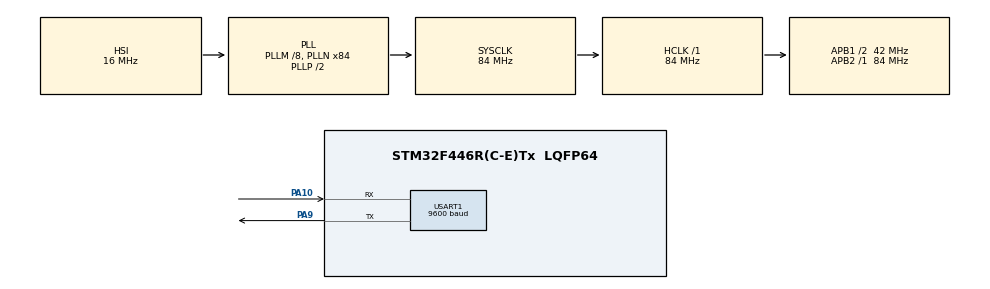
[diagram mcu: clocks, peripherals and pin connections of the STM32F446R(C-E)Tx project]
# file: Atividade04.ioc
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FREERTOS.Tasks01=Task01,24,128,StartTask01,Default,NULL,Dynamic,NULL,NULL;Task02,40,128,StartTask02,Default,NULL,Dynamic,NULL,NULL
FREERTOS.configUSE_NEWLIB_REENTRANT=1
Mcu.Family=STM32F4
Mcu.Name=STM32F446R(C-E)Tx
Mcu.Package=LQFP64
NVIC.PriorityGroup=NVIC_PRIORITYGROUP_4
NVIC.TIM1_UP_TIM10_IRQn=true\:15\:0\:false\:false\:true\:false\:false\:true\:true
NVIC.TimeBase=TIM1_UP_TIM10_IRQn
NVIC.TimeBaseIP=TIM1
PA10.Mode=Asynchronous
PA10.Signal=USART1_RX
PA13.Mode=Serial_Wire
PA13.Signal=SYS_JTMS-SWDIO
PA14.Mode=Serial_Wire
PA14.Signal=SYS_JTCK-SWCLK
PA9.Mode=Asynchronous
PA9.Signal=USART1_TX
ProjectManager.HeapSize=0x200
ProjectManager.StackSize=0x400
ProjectManager.TargetToolchain=STM32CubeIDE
RCC.AHBFreq_Value=84000000
RCC.APB1CLKDivider=RCC_HCLK_DIV2
RCC.APB1Freq_Value=42000000
RCC.APB1TimFreq_Value=84000000
RCC.APB2Freq_Value=84000000
RCC.APB2TimFreq_Value=84000000
RCC.CortexFreq_Value=84000000
RCC.FLatency-AdvancedSettings=FLASH_LATENCY_2
RCC.HCLKFreq_Value=84000000
RCC.HSE_VALUE=8000000
RCC.HSI_VALUE=16000000
RCC.LSE_VALUE=32768
RCC.PLLM=8
RCC.PLLN=84
RCC.SYSCLKFreq_VALUE=84000000
RCC.SYSCLKSource=RCC_SYSCLKSOURCE_PLLCLK
RCC.USBFreq_Value=84000000
RCC.VCOOutputFreq_Value=168000000
USART1.BaudRate=9600
USART1.VirtualMode=VM_ASYNC
VP_FREERTOS_VS_CMSIS_V2.Mode=CMSIS_V2
VP_SYS_VS_tim1.Mode=TIM1
board=NUCLEO-F446RE

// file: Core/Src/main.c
/* USER CODE BEGIN Header */
/**
  ******************************************************************************
  * @file           : main.c
  * @brief          : Main program body
  ******************************************************************************
  * @attention
  *
  * Copyright (c) 2025 STMicroelectronics.
  * All rights reserved.
  *
  * This software is licensed under terms that can be found in the LICENSE file
  * in the root directory of this software component.
  * If no LICENSE file comes with this software, it is provided AS-IS.
  *
  ******************************************************************************
  */
/* USER CODE END Header */
#include "main.h"
#include "cmsis_os.h"

/* USER CODE BEGIN Includes */
#include<stdio.h>

/* USER CODE END Includes */

UART_HandleTypeDef huart1;

/* Definitions for Task01 */
osThreadId_t Task01Handle;
const osThreadAttr_t Task01_attributes = {
  .name = "Task01",
  .stack_size = 128 * 4,
  .priority = (osPriority_t) osPriorityNormal,
};
/* Definitions for Task02 */
osThreadId_t Task02Handle;
const osThreadAttr_t Task02_attributes = {
  .name = "Task02",
  .stack_size = 128 * 4,
  .priority = (osPriority_t) osPriorityHigh,
};

void SystemClock_Config(void);
static void MX_GPIO_Init(void);
static void MX_USART1_UART_Init(void);
void StartTask01(void *argument);
void StartTask02(void *argument);

int main(void)
{

  /* MCU Configuration--------------------------------------------------------*/

  /* Reset of all peripherals, Initializes the Flash interface and the Systick. */
  HAL_Init();

  /* Configure the system clock */
  SystemClock_Config();

  /* Initialize all configured peripherals */
  MX_GPIO_Init();
  MX_USART1_UART_Init();

  /* Init scheduler */
  osKernelInitialize();

  /* Create the thread(s) */
  /* creation of Task01 */
  Task01Handle = osThreadNew(StartTask01, NULL, &Task01_attributes);

  /* creation of Task02 */
  Task02Handle = osThreadNew(StartTask02, NULL, &Task02_attributes);

  /* Start scheduler */
  osKernelStart();

  /* We should never get here as control is now taken by the scheduler */

  /* Infinite loop */
  while (1)
  {

  }
}

void SystemClock_Config(void)
{
  RCC_OscInitTypeDef RCC_OscInitStruct = {0};
  RCC_ClkInitTypeDef RCC_ClkInitStruct = {0};

  /** Configure the main internal regulator output voltage
  */
  __HAL_RCC_PWR_CLK_ENABLE();
  __HAL_PWR_VOLTAGESCALING_CONFIG(PWR_REGULATOR_VOLTAGE_SCALE3);

  /** Initializes the RCC Oscillators according to the specified parameters
  * in the RCC_OscInitTypeDef structure.
  */
  RCC_OscInitStruct.OscillatorType = RCC_OSCILLATORTYPE_HSI;
  RCC_OscInitStruct.HSIState = RCC_HSI_ON;
  RCC_OscInitStruct.HSICalibrationValue = RCC_HSICALIBRATION_DEFAULT;
  RCC_OscInitStruct.PLL.PLLState = RCC_PLL_ON;
  RCC_OscInitStruct.PLL.PLLSource = RCC_PLLSOURCE_HSI;
  RCC_OscInitStruct.PLL.PLLM = 8;
  RCC_OscInitStruct.PLL.PLLN = 84;
  RCC_OscInitStruct.PLL.PLLP = RCC_PLLP_DIV2;
  RCC_OscInitStruct.PLL.PLLQ = 2;
  RCC_OscInitStruct.PLL.PLLR = 2;
  if (HAL_RCC_OscConfig(&RCC_OscInitStruct) != HAL_OK)
  {
    Error_Handler();
  }

  /** Initializes the CPU, AHB and APB buses clocks
  */
  RCC_ClkInitStruct.ClockType = RCC_CLOCKTYPE_HCLK|RCC_CLOCKTYPE_SYSCLK
                              |RCC_CLOCKTYPE_PCLK1|RCC_CLOCKTYPE_PCLK2;
  RCC_ClkInitStruct.SYSCLKSource = RCC_SYSCLKSOURCE_PLLCLK;
  RCC_ClkInitStruct.AHBCLKDivider = RCC_SYSCLK_DIV1;
  RCC_ClkInitStruct.APB1CLKDivider = RCC_HCLK_DIV2;
  RCC_ClkInitStruct.APB2CLKDivider = RCC_HCLK_DIV1;

  if (HAL_RCC_ClockConfig(&RCC_ClkInitStruct, FLASH_LATENCY_2) != HAL_OK)
  {
    Error_Handler();
  }
}

static void MX_USART1_UART_Init(void)
{

  huart1.Instance = USART1;
  huart1.Init.BaudRate = 9600;
  huart1.Init.WordLength = UART_WORDLENGTH_8B;
  huart1.Init.StopBits = UART_STOPBITS_1;
  huart1.Init.Parity = UART_PARITY_NONE;
  huart1.Init.Mode = UART_MODE_TX_RX;
  huart1.Init.HwFlowCtl = UART_HWCONTROL_NONE;
  huart1.Init.OverSampling = UART_OVERSAMPLING_16;
  if (HAL_UART_Init(&huart1) != HAL_OK)
  {
    Error_Handler();
  }

}

static void MX_GPIO_Init(void)
{

  /* GPIO Ports Clock Enable */
  __HAL_RCC_GPIOA_CLK_ENABLE();

}

void StartTask01(void *argument)
{
  /* USER CODE BEGIN 5 */
	static uint32_t previous_ticket = 0;
	uint32_t current_ticket;
	char message[100];
	int size;
  /* Infinite loop */
  for(;;)
  {
	  osDelay(500);
	  current_ticket = osKernelGetTickCount();
	  size = sprintf(message,"O Valor do Ticket:%lu \r\n",current_ticket - previous_ticket);
	  HAL_UART_Transmit(&huart1,(uint8_t*)message, size,HAL_MAX_DELAY);

	  size = sprintf(message,"Current ticket :%lu e Previous Ticket :%lu ",current_ticket,previous_ticket);
	  HAL_UART_Transmit(&huart1, (uint8_t*)message, size,HAL_MAX_DELAY);

	  previous_ticket = current_ticket;

  }
  /* USER CODE END 5 */
}

void StartTask02(void *argument)
{
  /* USER CODE BEGIN StartTask02 */
	char message[100];
	int size;
  /* Infinite loop */
  for(;;)
  {
	  size = sprintf(message,"Tarefa 02 Sendo Executada\n");
	  HAL_UART_Transmit(&huart1,(uint8_t*)message, size,HAL_MAX_DELAY);
	  osDelay(100);
  }
  /* USER CODE END StartTask02 */
}

void HAL_TIM_PeriodElapsedCallback(TIM_HandleTypeDef *htim)
{
  if (htim->Instance == TIM1) {
    HAL_IncTick();
  }
}

void Error_Handler(void)
{
  __disable_irq();
  while (1)
  {
  }
}
